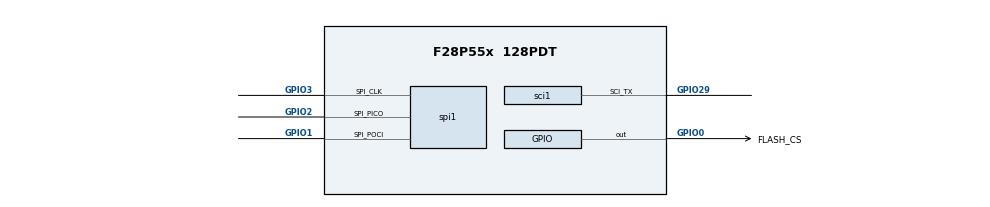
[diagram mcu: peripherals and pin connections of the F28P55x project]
/**
 * @cliArgs --device "F28P55x" --part "F28P55x_128PDT" --package "128PDT" --context "system" --product "C2000WARE@5.05.00.00"
 * @versions {"tool":"1.24.0+4110"}
 */

/**
 * Import the modules used in this configuration.
 */
const gpio  = scripting.addModule("/driverlib/gpio.js", {}, false);
const gpio1 = gpio.addInstance();
const sci   = scripting.addModule("/driverlib/sci.js", {}, false);
const sci1  = sci.addInstance();
const spi   = scripting.addModule("/driverlib/spi.js", {}, false);
const spi1  = spi.addInstance();

/**
 * Write custom configuration values to the imported modules.
 */
gpio1.$name           = "FLASH_CS";
gpio1.direction       = "GPIO_DIR_MODE_OUT";
gpio1.gpioPin.$assign = "GPIO0";

sci1.$name                 = "mySCI0";
sci1.useInterrupts         = false;
sci1.useFifo               = false;
sci1.sci.sci_txPin.$assign = "GPIO29";
sci1.rxQual.$name          = "myGPIOQUAL3";
sci1.txQual.$name          = "myGPIOQUAL4";

spi1.$name                   = "FLASH_SPI";
spi1.ptePolarity             = "SPI_PTE_ACTIVE_HIGH";
spi1.dataWidth               = "8";
spi1.useFifo                 = false;
spi1.useInterrupts           = false;
spi1.useCase                 = "CUSTOM";
spi1.useInterfacePins        = ["SPI@_CLK","SPI@_PICO","SPI@_POCI"];
spi1.mode                    = "SPI_MODE_CONTROLLER";
spi1.spi.spi_picoPin.$assign = "GPIO2";
spi1.spi.spi_pociPin.$assign = "GPIO1";
spi1.spi.spi_clkPin.$assign  = "GPIO3";
spi1.clkQual.$name           = "myGPIOQUAL2";
spi1.clkQual.qualMode        = "GPIO_QUAL_SYNC";
spi1.picoQual.$name          = "myGPIOQUAL0";
spi1.picoQual.qualMode       = "GPIO_QUAL_SYNC";
spi1.pociQual.$name          = "myGPIOQUAL1";
spi1.pociQual.qualMode       = "GPIO_QUAL_SYNC";

/**
 * Pinmux solution for unlocked pins/peripherals. This ensures that minor changes to the automatic solver in a future
 * version of the tool will not impact the pinmux you originally saw.  These lines can be completely deleted in order to
 * re-solve from scratch.
 */
sci1.sci.$suggestSolution           = "SCIA";
sci1.sci.sci_rxPin.$suggestSolution = "A16, B16, C16, GPIO28";
spi1.spi.$suggestSolution           = "SPIA";
